# STM32H755xx_CM4 register map
File version: 1.0
Registers are 32-bit, read-write, reset 0x0 unless marked. A register's access mark holds for its fields unless they carry their own. Offsets are from the block's base; [hi:lo] are bit positions; {n}, {i} and the like mark numbered series; 'fields as' and 'values as' point back to an identical list.

## MDMA — MDMA Controller
Base 0x52000000
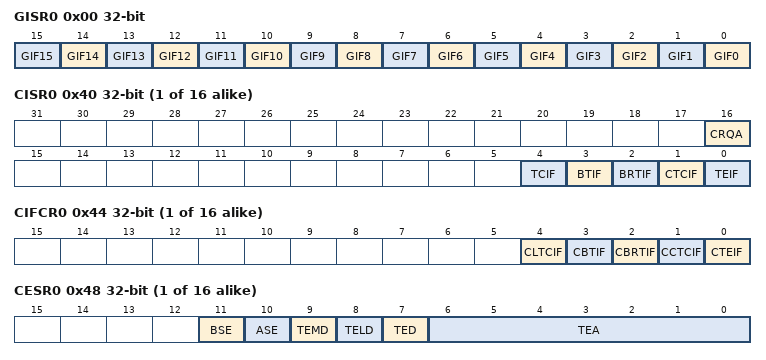
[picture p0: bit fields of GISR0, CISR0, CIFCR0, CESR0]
0x00 GISR0 — MDMA Global Interrupt/Status Register 0
  [n] GIF{n} (n=0..15) — Channel {n} global interrupt flag
{0x40+0x40*i} CISR{i} (i=0..15) — MDMA channel x interrupt/status register
  [16] CRQA — Channel x request Active flag
  [4] TCIF — Channel x buffer transfer complete interrupt flag
  [3] BTIF — Channel x block transfer complete interrupt flag
  [2] BRTIF — Channel x block repeat transfer complete interrupt flag
  [1] CTCIF — Channel x Channel Transfer Complete interrupt flag
  [0] TEIF — Channel x transfer error interrupt flag
{0x44+0x40*i} CIFCR{i} (i=0..15) — MDMA channel x interrupt flag clear register
  [4] CLTCIF — CLear Transfer buffer Complete Interrupt Flag for channel
  [3] CBTIF — Channel x Clear block transfer complete interrupt flag
  [2] CBRTIF — Channel x clear block repeat transfer complete interrupt flag
  [1] CCTCIF — Clear Channel transfer complete interrupt flag for channel x
  [0] CTEIF — Channel x clear transfer error interrupt flag
{0x48+0x40*i} CESR{i} (i=0..15) — MDMA Channel x error status register
  [11] BSE — Block Size Error
  [10] ASE — Address/Size Error
  [9] TEMD — Transfer Error Mask Data
  [8] TELD — Transfer Error Link Data
  [7] TED — Transfer Error Direction
  [6:0] TEA — Transfer Error Address
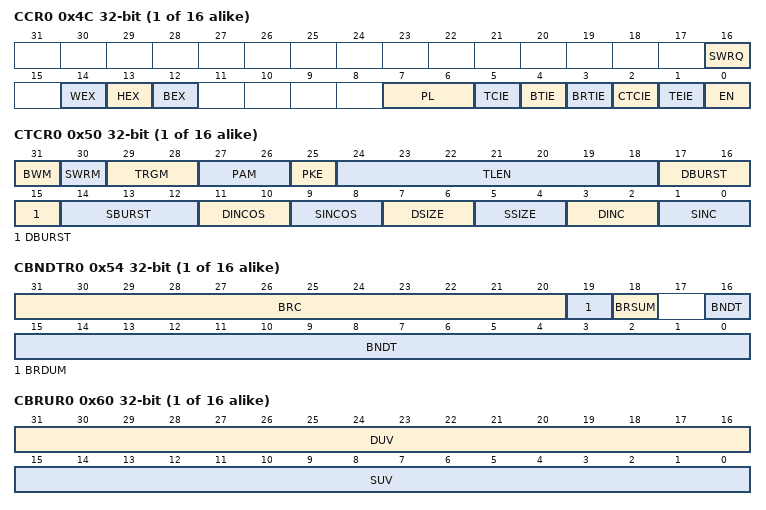
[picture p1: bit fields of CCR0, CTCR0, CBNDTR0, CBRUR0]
{0x4C+0x40*i} CCR{i} (i=0..15) — MDMA channel x control register
  [16] SWRQ — SW ReQuest
  [14] WEX — Word Endianness eXchange
  [13] HEX — Half word Endianness eXchange
  [12] BEX — Byte Endianness eXchange
  [7:6] PL — Priority level
  [5] TCIE — buffer Transfer Complete interrupt enable
  [4] BTIE — Block Transfer interrupt enable
  [3] BRTIE — Block Repeat transfer interrupt enable
  [2] CTCIE — Channel Transfer Complete interrupt enable
  [1] TEIE — Transfer error interrupt enable
  [0] EN — Channel enable / flag channel ready when read low
{0x50+0x40*i} CTCR{i} (i=0..15) — MDMA channel x Transfer Configuration register
  [31] BWM — Bufferable Write Mode
  [30] SWRM — SW Request Mode
  [29:28] TRGM — Trigger Mode
  [27:26] PAM — Padding/Alignment Mode
  [25] PKE — PacK Enable
  [24:18] TLEN — buffer Transfer Length (number of bytes - 1)
  [17:15] DBURST — Destination burst transfer configuration
  [14:12] SBURST — Source burst transfer configuration
  [11:10] DINCOS — Destination increment offset size
  [9:8] SINCOS — Source increment offset size
  [7:6] DSIZE — Destination data size
  [5:4] SSIZE — Source data size
  [3:2] DINC — Source increment mode
  [1:0] SINC — Source increment mode
{0x54+0x40*i} CBNDTR{i} (i=0..15) — MDMA Channel x block number of data register
  [31:20] BRC — Block Repeat Count
  [19] BRDUM — Block Repeat Destination address Update Mode
  [18] BRSUM — Block Repeat Source address Update Mode
  [16:0] BNDT — Block Number of data bytes to transfer
{0x58+0x40*i} CSAR{i} (i=0..15) — MDMA channel x source address register
  [31:0] SAR — Source address
{0x5C+0x40*i} CDAR{i} (i=0..15) — MDMA channel x destination address register
  [31:0] DAR — Destination address
{0x60+0x40*i} CBRUR{i} (i=0..15) — MDMA channel x Block Repeat address Update register
  [31:16] DUV — Destination address Update Value
  [15:0] SUV — Source address Update Value
{0x64+0x40*i} CLAR{i} (i=0..15) — MDMA channel x Link Address register
  [31:0] LAR — Link Address Register
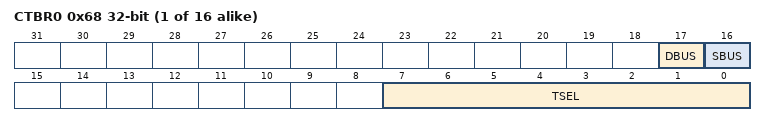
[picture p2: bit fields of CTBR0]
{0x68+0x40*i} CTBR{i} (i=0..15) — MDMA channel x Trigger and Bus selection Register
  [17] DBUS — Destination BUS select
  [16] SBUS — Source BUS select
  [7:0] TSEL — Trigger SELection
{0x70+0x40*i} CMAR{i} (i=0..15) — MDMA channel x Mask address register
  [31:0] MAR — Mask address
{0x74+0x40*i} CMDR{i} (i=0..15) — MDMA channel x Mask Data register
  [31:0] MDR — Mask Data

## FMC_Bank1_R — Flexible Memory Controller
Base 0x52004000
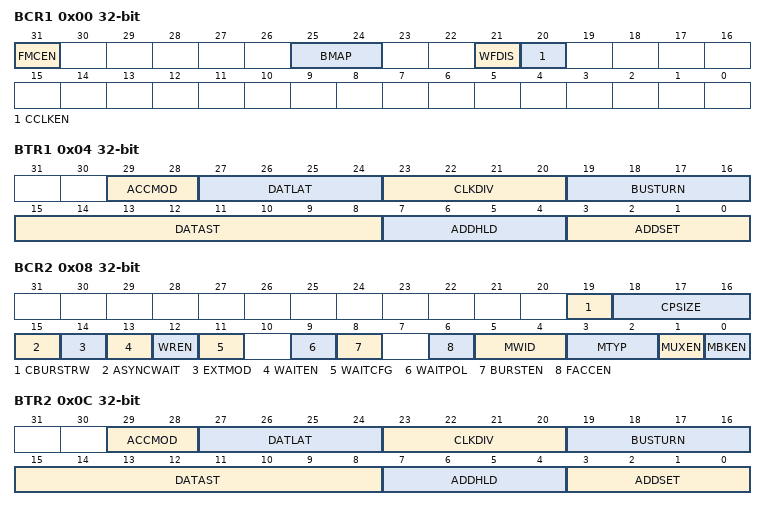
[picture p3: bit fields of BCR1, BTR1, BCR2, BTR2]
0x00 BCR1 — NOR/PSRAM chip-select control register(BCR) and chip-select timing register(BTR)
  [31] FMCEN — FMC controller Enable
  [25:24] BMAP — BMAP[1:0] FMC bank mapping
  [21] WFDIS — Write FIFO Disable
  [20] CCLKEN — Continuous clock enable
0x04 BTR1 — NOR/PSRAM chip-select control register(BCR) and chip-select timing register(BTR)
  [29:28] ACCMOD — ACCMOD[1:0] bits (Access mode)
  [27:24] DATLAT — DATLA[3:0] bits (Data latency)
  [23:20] CLKDIV — CLKDIV[3:0] bits (Clock divide ratio)
  [19:16] BUSTURN — BUSTURN[3:0] bits (Bus turnaround phase duration)
  [15:8] DATAST — DATAST [3:0] bits (Data-phase duration)
  [7:4] ADDHLD — ADDHLD[3:0] bits (Address-hold phase duration)
  [3:0] ADDSET — ADDSET[3:0] bits (Address setup phase duration)
0x08 BCR2 — NOR/PSRAM chip-select control register(BCR) and chip-select timing register(BTR)
  [19] CBURSTRW — Write burst enable
  [18:16] CPSIZE — PSIZE[2:0] bits CRAM Page Size
  [15] ASYNCWAIT — Asynchronous wait
  [14] EXTMOD — Extended mode enable
  [13] WAITEN — Wait enable bit
  [12] WREN — Write enable bit
  [11] WAITCFG — Wait timing configuration
  [9] WAITPOL — Wait signal polarity bit
  [8] BURSTEN — Burst enable bit
  [6] FACCEN — Flash access enable
  [5:4] MWID — MWID[1:0] bits (Memory data bus width)
  [3:2] MTYP — MTYP[1:0] bits (Memory type)
  [1] MUXEN — Address/data multiplexing enable bit
  [0] MBKEN — Memory bank enable bit
0x0C BTR2 — NOR/PSRAM chip-select control register(BCR) and chip-select timing register(BTR)
  fields as BTR1
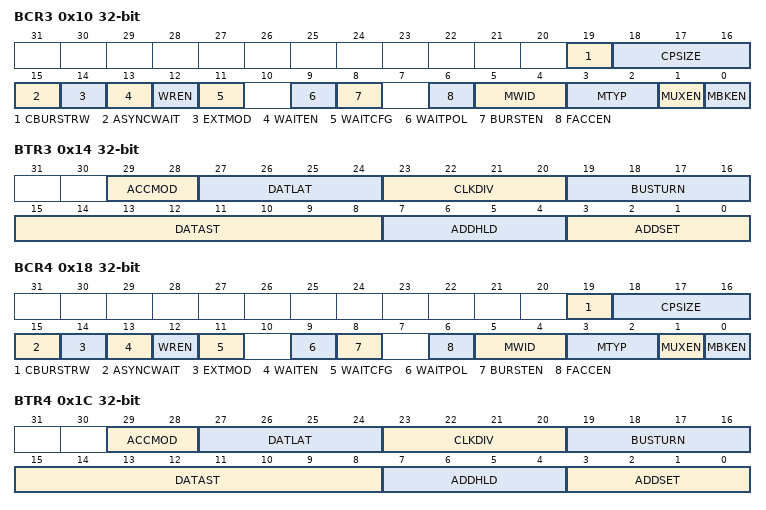
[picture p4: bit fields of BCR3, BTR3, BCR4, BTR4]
0x10 BCR3 — NOR/PSRAM chip-select control register(BCR) and chip-select timing register(BTR)
  fields as BCR2
0x14 BTR3 — NOR/PSRAM chip-select control register(BCR) and chip-select timing register(BTR)
  fields as BTR1
0x18 BCR4 — NOR/PSRAM chip-select control register(BCR) and chip-select timing register(BTR)
  fields as BCR2
0x1C BTR4 — NOR/PSRAM chip-select control register(BCR) and chip-select timing register(BTR)
  fields as BTR1
